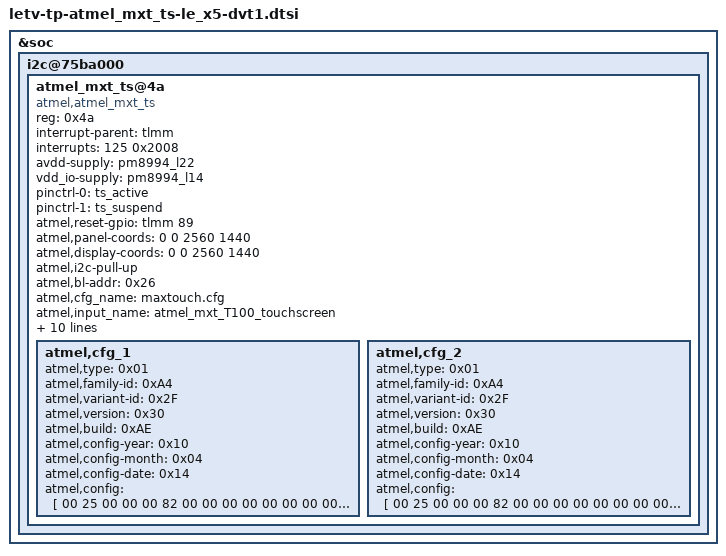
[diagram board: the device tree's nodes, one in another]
&soc {
	i2c@75ba000 {
		atmel_mxt_ts@4a {
			compatible = "atmel,atmel_mxt_ts";
			reg = <0x4a>;
			interrupt-parent = <&tlmm>;
			interrupts = <125 0x2008>;
			avdd-supply = <&pm8994_l22>;
			vdd_io-supply = <&pm8994_l14>;
			pinctrl-names = "pmx_ts_active", "pmx_ts_suspend";
			pinctrl-0 = <&ts_active>;
			pinctrl-1 = <&ts_suspend>;
			atmel,reset-gpio = <&tlmm 89 0>;
			atmel,panel-coords = <0 0 2560 1440>;
			atmel,display-coords = <0 0 2560 1440>;
			atmel,i2c-pull-up;
			atmel,bl-addr = <0x26>;
			atmel,cfg_name = "maxtouch.cfg";
			atmel,input_name = "atmel_mxt_T100_touchscreen";
			atmel,fw_version = "30AE";
			atmel,number-of-x-lines = <27>;
			atmel,number-of-y-lines = <16>;
			atmel,rawdata_threshold_max = <30500>;
			atmel,rawdata_threshold_min = <24500>;
			atmel,rawdata_shift_value = <4000>;
			atmel,rawdata_tkey_threshold_max = <26500>;
			atmel,rawdata_tkey_threshold_min = <21500>;
			atmel,rawdata_tkey_shift_value = <3500>;
			atmel,cap-button-codes = <158 172 0x244>;
			status = "ok";
			atmel,cfg_1 {
				atmel,type = <0x01>;
				atmel,family-id = <0xA4>;
				atmel,variant-id = <0x2F>;
				atmel,version = <0x30>;
				atmel,build = <0xAE>;
				atmel,config-year = <0x10>;
				atmel,config-month = <0x04>;
				atmel,config-date = <0x14>;
				atmel,config = [
					00 25 00 00 00 82 00 00
					00 00 00 00 00 00 00 00
					00 00 00 00 00 00 00 00
					00 00 00 00 00 00 00 00
					00 00 00 00 00 00 00 00
					00 00 00 00 00 00 00 00
					00 00 00 00 00 00 00 00
					00 00 00 00 00 00 00 00
					00 00 00 00 00 00 00 00
					00 00 00 00 00 00 00 00
					00 00 00 00 00 00 00 00
					00 00 00 00 00 00 00 00
					00 00 00 00 00 00 00 00
					00 00 00 00 00 00 00 00
					00 00 00 00 00 00 00 00
					00 00 00 00 00 00 00 00
					00 00 00 00 00 00 00 00
					00 44 00 00 00 49 00 00
					00 00 00 00 00 00 00 00
					00 00 00 00 00 00 00 00
					00 00 00 00 00 00 00 00
					00 00 00 00 00 00 00 00
					00 00 00 00 00 00 00 00
					00 00 00 00 00 00 00 00
					00 00 00 00 00 00 00 00
					00 00 00 00 00 00 00 00
					00 00 00 00 00 00 00
					00 26 00 00 00 40 01 1E
					AE 10 04 14 00 00 00 00
					00 00 00 00 00 00 00 00
					00 00 00 00 00 00 00 00
					00 00 00 00 00 00 00 00
					00 00 00 00 00 00 00 00
					00 00 00 00 00 00 00 00
					00 00 00 00 00 00 00 00
					00 00 00 00 00 00
					00 47 00 00 00 C8 00 64
					14 32 0A 22 3C 14 19 00
					32 14 14 00 00 1E C8 0F
					00 02 00 14 00 32 02 F0
					78 32 00 00 00 00 64 14
					32 0A 22 3C 14 19 00 00
					32 14 14 00 00 1E C8 0F
					00 02 00 14 00 32 02 F0
					78 32 00 00 84 00 50 0A
					19 04 22 28 0A 0F 00 00
					20 0F 14 00 50 0F 32 05
					00 01 00 00 00 0C 43 FA
					3C 1E 00 00 85 00 01 01
					02 02 00 00 00 1C 01 19
					01 19 00 00 00 00 00 00
					00 00 00 00 00 00 18 0C
					00 00 00 14 14 0A 00 00
					0F 0F 05 00 00 14 14 14
					00 00 01 0F 01 01 00 00
					00 00 00 00 00 00 00 00
					00 00 00 00 00 00 00 00
					00 00 00 00 00 00 00 00
					00 00 00 00 00 00 00 00
					00 00 00 00 00 00 00 00
					00 00 00 00 00 00 00 00
					00 00 00 00 00 00
					00 6E 00 00 00 28 89 03
					51 03 89 05 B9 04 E1 05
					91 06 89 09 E9 08 A1 0A
					81 0B 51 09 61 09 59 0B
					49 0A E1 09 01 07 01 00
					01 00 01 00 01 00
					00 6E 00 01 00 28 00 00
					00 00 00 00 00 00 00 00
					00 00 00 00 00 00 00 00
					00 00 00 00 00 00 00 00
					00 00 00 00 00 00 00 00
					00 00 00 00 00 00
					00 6E 00 02 00 28 00 00
					00 00 00 00 00 00 00 00
					00 00 00 00 00 00 00 00
					00 00 00 00 00 00 00 00
					00 00 00 00 00 00 00 00
					00 00 00 00 00 00
					00 6E 00 03 00 28 D1 03
					39 04 39 05 79 05 F1 05
					41 07 E9 09 21 09 11 0B
					21 0B 41 09 59 09 49 0B
					51 0B 51 0A 31 08 01 00
					01 00 01 00 01 00
					00 6E 00 04 00 28 00 00
					00 00 00 00 00 00 00 00
					00 00 00 00 00 00 00 00
					00 00 00 00 00 00 00 00
					00 00 00 00 00 00 00 00
					00 00 00 00 00 00
					00 6E 00 05 00 28 00 00
					00 00 00 00 00 00 00 00
					00 00 00 00 00 00 00 00
					00 00 00 00 00 00 00 00
					00 00 00 00 00 00 00 00
					00 00 00 00 00 00
					00 6E 00 06 00 28 6B 04
					6B 04 53 04 63 04 53 04
					43 04 2B 04 2B 04 0B 04
					03 04 1B 04 23 04 0B 04
					13 04 1B 04 3B 04 03 00
					03 00 03 00 03 00
					00 6E 00 07 00 28 00 00
					00 00 00 00 00 00 00 00
					00 00 00 00 00 00 00 00
					00 00 00 00 00 00 00 00
					00 00 00 00 00 00 00 00
					00 00 00 00 00 00
					00 6E 00 08 00 28 00 00
					00 00 00 00 00 00 00 00
					00 00 00 00 00 00 00 00
					00 00 00 00 00 00 00 00
					00 00 00 00 00 00 00 00
					00 00 00 00 00 00
					00 07 00 00 00 05 08 08
					1E C2 00
					00 08 00 00 00 0F 50 00
					05 05 00 05 00 00 00 00
					0B 08 01 01 80
					00 0F 00 00 00 0B 8B 1C
					10 01 03 00 07 32 02 05
					00
					00 12 00 00 00 02 00 00
					00 13 00 00 00 06 00 00
					00 00 00 00
					00 19 00 00 00 10 03 00
					30 75 D8 59 00 00 00 00
					FE A0 0F 00 00 00
					00 28 00 00 00 07 31 00
					00 3C 3C 00 01
					00 2A 00 00 00 0E 01 00
					FF 2D FF 05 00 00 00 00
					C8 03 00 00
					00 2B 00 00 00 11 00 00
					00 00 00 00 00 00 00 00
					00 00 00 00 00 00 00
					00 2E 00 00 00 0C 00 00
					08 06 01 00 00 32 00 01
					00 00
					00 2F 00 00 00 2F 00 00
					00 00 00 00 00 00 00 00
					00 00 00 00 00 00 00 00
					00 00 00 00 00 00 00 00
					00 00 00 00 00 00 00 00
					00 00 00 00 00 00 00 00
					00 00 00 00 00
					00 38 00 00 00 24 03 00
					01 2F 04 04 04 04 04 04
					04 04 04 04 04 04 04 04
					04 04 04 04 04 04 04 04
					04 04 07 07 08 07 00 00
					00 00
					00 3D 00 00 00 05 03 00
					00 E8 03
					00 3D 00 01 00 05 00 00
					00 00 00
					00 3D 00 02 00 05 00 00
					00 00 00
					00 3D 00 03 00 05 00 00
					00 00 00
					00 3D 00 04 00 05 00 00
					00 00 00
					00 3D 00 05 00 05 00 00
					00 00 00
					00 41 00 00 00 17 81 0A
					00 00 00 00 00 00 00 00
					0A 00 00 00 00 00 00 12
					00 00 00 00 00
					00 41 00 01 00 17 00 00
					00 00 00 00 00 00 00 00
					00 00 00 00 00 00 00 00
					00 00 00 00 00
					00 41 00 02 00 17 00 00
					00 00 00 00 00 00 00 00
					00 00 00 00 00 00 00 00
					00 00 00 00 00
					00 46 00 00 00 0A 03 C8
					00 26 00 00 3F 00 00 00
					00 46 00 01 00 0A 03 78
					00 68 00 00 02 01 00 07
					00 46 00 02 00 0A 03 78
					00 64 00 00 1E 0A 00 11
					00 46 00 03 00 0A 00 78
					00 50 00 00 01 1F 00 00
					00 46 00 04 00 0A 03 72
					00 68 00 00 02 20 00 07
					00 46 00 05 00 0A 03 72
					00 64 00 00 1E 2A 00 11
					00 46 00 06 00 0A 00 72
					00 4E 00 00 00 3E 00 00
					00 46 00 07 00 0A 00 72
					00 50 00 00 01 3F 00 00
					00 46 00 08 00 0A 03 0D
					00 68 00 00 02 40 00 07
					00 46 00 09 00 0A 03 0D
					00 64 00 00 1E 4A 00 11
					00 46 00 0A 00 0A 00 0D
					00 4E 00 00 00 5E 00 00
					00 46 00 0B 00 0A 00 0D
					00 50 00 00 01 5F 00 00
					00 46 00 0C 00 0A 03 79
					00 3D 00 00 01 60 00 00
					00 46 00 0D 00 0A 03 73
					00 3D 00 00 01 61 00 00
					00 46 00 0E 00 0A 03 78
					00 3D 00 00 01 62 00 00
					00 46 00 0F 00 0A 03 72
					00 3D 00 00 01 63 00 00
					00 46 00 10 00 0A 00 00
					00 00 00 00 00 00 00 00
					00 46 00 11 00 0A 00 00
					00 00 00 00 00 00 00 00
					00 46 00 12 00 0A 03 16
					00 2E 00 00 04 6A 00 00
					00 46 00 13 00 0A 03 16
					00 48 00 00 13 6B 00 00
					00 46 00 14 00 0A 03 18
					00 2E 00 00 04 68 00 00
					00 46 00 15 00 0A 03 18
					00 48 00 00 13 69 00 00
					00 46 00 16 00 0A 03 18
					00 64 00 00 2B 79 00 00
					00 46 00 17 00 0A 03 1A
					00 48 00 00 13 67 00 00
					00 46 00 18 00 0A 00 00
					00 00 00 00 00 00 00 00
					00 46 00 19 00 0A 03 1A
					00 2E 00 00 04 66 00 00
					00 46 00 1A 00 0A 03 1A
					00 64 00 00 2B 78 00 00
					00 46 00 1B 00 0A 03 18
					00 64 00 00 20 7D 00 00
					00 46 00 1C 00 0A 03 1A
					00 64 00 00 20 7E 00 00
					00 46 00 1D 00 0A 03 16
					00 64 00 00 20 7F 00 00
					00 46 00 1E 00 0A 00 18
					00 41 00 00 01 82 00 00
					00 46 00 1F 00 0A 00 1A
					00 41 00 00 01 83 00 00
					00 46 00 20 00 0A 00 16
					00 41 00 00 01 84 00 00
					00 46 00 21 00 0A 01 18
					00 47 00 00 4C 87 00 00
					00 46 00 22 00 0A 01 1A
					00 47 00 00 4C 88 00 00
					00 46 00 23 00 0A 01 16
					00 47 00 00 4C 89 00 00
					00 46 00 24 00 0A 01 13
					00 06 00 00 02 8C 00 00
					00 46 00 25 00 0A 01 13
					00 64 00 00 1F 8D 00 00
					00 46 00 26 00 0A 01 12
					00 64 00 00 1F 8E 00 00
					00 46 00 27 00 0A 00 0B
					00 06 00 00 02 8F 00 00
					00 48 00 00 00 59 7D 00
					00 01 00 04 0A 0A 00 08
					2D 00 00 04 31 37 65 0E
					00 19 09 00 00 00 00 00
					0A 00 00 00 00 0C 00 00
					00 00 00 00 0D 00 09 00
					00 00 00 00 0C 00 00 00
					00 0C 00 00 00 00 00 02
					1E 85 09 69 94 C6 6E 00
					20 20 20 20 00 28 28 28
					28 00 00 03 00 85 00 00
					00 00 00 00 00 00 00
					00 4D 00 00 00 02 00 00
					00 4E 00 00 00 0C 84 05
					03 0A 19 01 18 00 8C 00
					00 00
					00 4F 00 00 00 04 00 00
					00 00
					00 4F 00 01 00 04 00 00
					00 00
					00 4F 00 02 00 04 00 00
					00 00
					00 50 00 00 00 0E 03 00
					6E 14 0A C5 00 46 1E 01
					00 00 00 03
					00 51 00 00 00 12 00 00
					00 00 00 00 00 00 00 00
					00 00 00 00 00 00 00 00
					00 51 00 01 00 12 00 00
					00 00 00 00 00 00 00 00
					00 00 00 00 00 00 00 00
					00 54 00 00 00 04 00 00
					00 00
					00 5D 00 00 00 1E 0F 9F
					05 00 00 00 00 F6 09 FF
					0F FF 0F 00 64 00 14 04
					00 00 2C 01 2C 01 00 14
					00 14 00 00
					00 63 00 00 00 0C 00 00
					00 00 00 00 00 00 00 00
					00 00
					00 64 00 00 00 45 83 35
					01 01 00 00 0A 88 00 1C
					2D 09 0A FF 09 17 20 23
					31 00 10 2D 04 04 9F 05
					1F 2F 0C 09 28 0F 19 00
					50 0F 32 05 00 01 00 00
					00 0C 43 FA 3C 1E 00 1E
					00 64 14 05 00 00 A3 31
					A6 2D 00 25 00 00 32 96
					00 19 87
					00 65 00 00 00 20 00 00
					00 00 00 00 00 00 00 00
					00 00 00 00 00 00 00 00
					00 00 00 00 00 00 00 00
					00 00 00 00 00 00
					00 68 00 00 00 0B 01 00
					50 0A 19 04 22 28 0A 0F
					06
					00 6C 00 00 00 4B 9D 00
					00 01 01 00 00 04 00 00
					00 00 00 00 00 00 00 00
					00 20 00 00 00 00 20 00
					00 00 00 00 00 06 00 01
					00 00 00 00 00 30 00 00
					00 00 30 00 00 00 00 00
					03 0C 64 01 00 00 00 00
					00 40 00 00 00 00 40 00
					00 00 00 00 14 00 85 00
					00
					00 6D 00 00 00 09 42 00
					05 00 00 00 00 00 03
					00 6F 00 00 00 1E 00 00
					55 50 18 18 05 05 00 FF
					00 00 00 00 00 00 00 00
					05 00 35 DC 00 23 00 01
					0A 00 32 3C
					00 6F 00 01 00 1E 00 00
					00 00 00 00 00 00 00 00
					00 00 00 00 00 00 00 00
					00 00 00 00 00 00 00 01
					00 00 00 00
					00 6F 00 02 00 1E 00 00
					55 50 40 40 00 00 00 00
					00 00 00 00 00 00 00 00
					00 00 00 00 00 2D 00 01
					00 00 00 00
					00 70 00 00 00 05 00 00
					00 00 00
					00 70 00 01 00 05 00 00
					00 00 00
					00 71 00 00 00 03 05 00
					08
					00 73 00 00 00 14 06 00
					00 FF FF 00 00 FF FF 28
					00 3C 00 02 3E 02 00 86
					00 23
					00 74 00 00 00 FF 00 00
					00 00 00 00 00 00 00 00
					00 00 00 00 00 00 00 00
					00 00 00 00 00 00 00 00
					00 00 00 00 00 00 00 00
					00 00 00 00 00 00 00 00
					00 00 00 00 00 00 00 00
					00 00 00 00 00 00 00 00
					00 00 00 00 00 00 00 00
					00 00 00 00 00 00 00 00
					00 00 00 00 00 00 00 00
					00 00 00 00 00 00 00 00
					00 00 00 00 00 00 00 00
					00 00 00 00 00 00 00 00
					00 00 00 00 00 00 00 00
					00 00 00 00 00 00 00 00
					00 00 00 00 00 00 00 00
					00 00 00 00 00 00 00 00
					00 00 00 00 00 00 00 00
					00 00 00 00 00 00 00 00
					00 00 00 00 00 00 00 00
					00 00 00 00 00 00 00 00
					00 00 00 00 00 00 00 00
					00 00 00 00 00 00 00 00
					00 00 00 00 00 00 00 00
					00 00 00 00 00 00 00 00
					00 00 00 00 00 00 00 00
					00 00 00 00 00 00 00 00
					00 00 00 00 00 00 00 00
					00 00 00 00 00 00 00 00
					00 00 00 00 00 00 00 00
					00 00 00 00 00 00 00 00
					00 00 00 00 00
					00 79 00 00 00 03 00 00
					00
					00 7C 00 00 00 07 0B 01
					07 08 80 3E 82
					00 7D 00 00 00 01 03
				];
			};
			atmel,cfg_2 {
				atmel,type = <0x01>;
				atmel,family-id = <0xA4>;
				atmel,variant-id = <0x2F>;
				atmel,version = <0x30>;
				atmel,build = <0xAE>;
				atmel,config-year = <0x10>;
				atmel,config-month = <0x04>;
				atmel,config-date = <0x14>;
				atmel,config = [
					00 25 00 00 00 82 00 00
					00 00 00 00 00 00 00 00
					00 00 00 00 00 00 00 00
					00 00 00 00 00 00 00 00
					00 00 00 00 00 00 00 00
					00 00 00 00 00 00 00 00
					00 00 00 00 00 00 00 00
					00 00 00 00 00 00 00 00
					00 00 00 00 00 00 00 00
					00 00 00 00 00 00 00 00
					00 00 00 00 00 00 00 00
					00 00 00 00 00 00 00 00
					00 00 00 00 00 00 00 00
					00 00 00 00 00 00 00 00
					00 00 00 00 00 00 00 00
					00 00 00 00 00 00 00 00
					00 00 00 00 00 00 00 00
					00 44 00 00 00 49 00 00
					00 00 00 00 00 00 00 00
					00 00 00 00 00 00 00 00
					00 00 00 00 00 00 00 00
					00 00 00 00 00 00 00 00
					00 00 00 00 00 00 00 00
					00 00 00 00 00 00 00 00
					00 00 00 00 00 00 00 00
					00 00 00 00 00 00 00 00
					00 00 00 00 00 00 00
					00 26 00 00 00 40 01 1E
					AE 10 04 14 00 00 00 00
					00 00 00 00 00 00 00 00
					00 00 00 00 00 00 00 00
					00 00 00 00 00 00 00 00
					00 00 00 00 00 00 00 00
					00 00 00 00 00 00 00 00
					00 00 00 00 00 00 00 00
					00 00 00 00 00 00
					00 47 00 00 00 C8 00 64
					14 32 0A 22 3C 14 19 00
					32 14 14 00 00 1E C8 0F
					00 02 00 14 00 32 02 F0
					78 32 00 00 00 00 64 14
					32 0A 22 3C 14 19 00 00
					32 14 14 00 00 1E C8 0F
					00 02 00 14 00 32 02 F0
					78 32 00 00 84 00 50 0A
					19 04 22 28 0A 0F 00 00
					20 0F 14 00 50 0F 32 05
					00 01 00 00 00 0C 43 FA
					3C 1E 00 00 85 00 01 01
					02 02 00 00 00 1C 01 19
					01 19 00 00 00 00 00 00
					00 00 00 00 00 00 18 0C
					00 00 00 14 14 0A 00 00
					0F 0F 05 00 00 14 14 14
					00 00 01 0F 01 01 00 00
					00 00 00 00 00 00 00 00
					00 00 00 00 00 00 00 00
					00 00 00 00 00 00 00 00
					00 00 00 00 00 00 00 00
					00 00 00 00 00 00 00 00
					00 00 00 00 00 00 00 00
					00 00 00 00 00 00
					00 6E 00 00 00 28 89 03
					51 03 89 05 B9 04 E1 05
					91 06 89 09 E9 08 A1 0A
					81 0B 51 09 61 09 59 0B
					49 0A E1 09 01 07 01 00
					01 00 01 00 01 00
					00 6E 00 01 00 28 00 00
					00 00 00 00 00 00 00 00
					00 00 00 00 00 00 00 00
					00 00 00 00 00 00 00 00
					00 00 00 00 00 00 00 00
					00 00 00 00 00 00
					00 6E 00 02 00 28 00 00
					00 00 00 00 00 00 00 00
					00 00 00 00 00 00 00 00
					00 00 00 00 00 00 00 00
					00 00 00 00 00 00 00 00
					00 00 00 00 00 00
					00 6E 00 03 00 28 D1 03
					39 04 39 05 79 05 F1 05
					41 07 E9 09 21 09 11 0B
					21 0B 41 09 59 09 49 0B
					51 0B 51 0A 31 08 01 00
					01 00 01 00 01 00
					00 6E 00 04 00 28 00 00
					00 00 00 00 00 00 00 00
					00 00 00 00 00 00 00 00
					00 00 00 00 00 00 00 00
					00 00 00 00 00 00 00 00
					00 00 00 00 00 00
					00 6E 00 05 00 28 00 00
					00 00 00 00 00 00 00 00
					00 00 00 00 00 00 00 00
					00 00 00 00 00 00 00 00
					00 00 00 00 00 00 00 00
					00 00 00 00 00 00
					00 6E 00 06 00 28 6B 04
					6B 04 53 04 63 04 53 04
					43 04 2B 04 2B 04 0B 04
					03 04 1B 04 23 04 0B 04
					13 04 1B 04 3B 04 03 00
					03 00 03 00 03 00
					00 6E 00 07 00 28 00 00
					00 00 00 00 00 00 00 00
					00 00 00 00 00 00 00 00
					00 00 00 00 00 00 00 00
					00 00 00 00 00 00 00 00
					00 00 00 00 00 00
					00 6E 00 08 00 28 00 00
					00 00 00 00 00 00 00 00
					00 00 00 00 00 00 00 00
					00 00 00 00 00 00 00 00
					00 00 00 00 00 00 00 00
					00 00 00 00 00 00
					00 07 00 00 00 05 08 08
					1E C2 00
					00 08 00 00 00 0F 50 00
					05 05 00 05 00 00 00 00
					0B 08 01 01 80
					00 0F 00 00 00 0B 8B 1C
					10 01 03 00 07 32 02 05
					00
					00 12 00 00 00 02 00 00
					00 13 00 00 00 06 00 00
					00 00 00 00
					00 19 00 00 00 10 03 00
					30 75 D8 59 00 00 00 00
					FE A0 0F 00 00 00
					00 28 00 00 00 07 31 00
					00 3C 3C 00 01
					00 2A 00 00 00 0E 01 00
					FF 2D FF 05 00 00 00 00
					C8 03 00 00
					00 2B 00 00 00 11 00 00
					00 00 00 00 00 00 00 00
					00 00 00 00 00 00 00
					00 2E 00 00 00 0C 00 00
					08 06 01 00 00 32 00 01
					00 00
					00 2F 00 00 00 2F 00 00
					00 00 00 00 00 00 00 00
					00 00 00 00 00 00 00 00
					00 00 00 00 00 00 00 00
					00 00 00 00 00 00 00 00
					00 00 00 00 00 00 00 00
					00 00 00 00 00
					00 38 00 00 00 24 03 00
					01 2F 04 04 04 04 04 04
					04 04 04 04 04 04 04 04
					04 04 04 04 04 04 04 04
					04 04 07 07 08 07 00 00
					00 00
					00 3D 00 00 00 05 03 00
					00 E8 03
					00 3D 00 01 00 05 00 00
					00 00 00
					00 3D 00 02 00 05 00 00
					00 00 00
					00 3D 00 03 00 05 00 00
					00 00 00
					00 3D 00 04 00 05 00 00
					00 00 00
					00 3D 00 05 00 05 00 00
					00 00 00
					00 41 00 00 00 17 81 0A
					00 00 00 00 00 00 00 00
					0A 00 00 00 00 00 00 12
					00 00 00 00 00
					00 41 00 01 00 17 00 00
					00 00 00 00 00 00 00 00
					00 00 00 00 00 00 00 00
					00 00 00 00 00
					00 41 00 02 00 17 00 00
					00 00 00 00 00 00 00 00
					00 00 00 00 00 00 00 00
					00 00 00 00 00
					00 46 00 00 00 0A 03 C8
					00 26 00 00 3F 00 00 00
					00 46 00 01 00 0A 03 78
					00 68 00 00 02 01 00 07
					00 46 00 02 00 0A 03 78
					00 64 00 00 1E 0A 00 11
					00 46 00 03 00 0A 00 78
					00 50 00 00 01 1F 00 00
					00 46 00 04 00 0A 03 72
					00 68 00 00 02 20 00 07
					00 46 00 05 00 0A 03 72
					00 64 00 00 1E 2A 00 11
					00 46 00 06 00 0A 00 72
					00 4E 00 00 00 3E 00 00
					00 46 00 07 00 0A 00 72
					00 50 00 00 01 3F 00 00
					00 46 00 08 00 0A 03 0D
					00 68 00 00 02 40 00 07
					00 46 00 09 00 0A 03 0D
					00 64 00 00 1E 4A 00 11
					00 46 00 0A 00 0A 00 0D
					00 4E 00 00 00 5E 00 00
					00 46 00 0B 00 0A 00 0D
					00 50 00 00 01 5F 00 00
					00 46 00 0C 00 0A 03 79
					00 3D 00 00 01 60 00 00
					00 46 00 0D 00 0A 03 73
					00 3D 00 00 01 61 00 00
					00 46 00 0E 00 0A 03 78
					00 3D 00 00 01 62 00 00
					00 46 00 0F 00 0A 03 72
					00 3D 00 00 01 63 00 00
					00 46 00 10 00 0A 00 00
					00 00 00 00 00 00 00 00
					00 46 00 11 00 0A 00 00
					00 00 00 00 00 00 00 00
					00 46 00 12 00 0A 03 16
					00 2E 00 00 04 6A 00 00
					00 46 00 13 00 0A 03 16
					00 48 00 00 13 6B 00 00
					00 46 00 14 00 0A 03 18
					00 2E 00 00 04 68 00 00
					00 46 00 15 00 0A 03 18
					00 48 00 00 13 69 00 00
					00 46 00 16 00 0A 03 18
					00 64 00 00 2B 79 00 00
					00 46 00 17 00 0A 03 1A
					00 48 00 00 13 67 00 00
					00 46 00 18 00 0A 00 00
					00 00 00 00 00 00 00 00
					00 46 00 19 00 0A 03 1A
					00 2E 00 00 04 66 00 00
					00 46 00 1A 00 0A 03 1A
					00 64 00 00 2B 78 00 00
					00 46 00 1B 00 0A 03 18
					00 64 00 00 20 7D 00 00
					00 46 00 1C 00 0A 03 1A
					00 64 00 00 20 7E 00 00
					00 46 00 1D 00 0A 03 16
					00 64 00 00 20 7F 00 00
					00 46 00 1E 00 0A 00 18
					00 41 00 00 01 82 00 00
					00 46 00 1F 00 0A 00 1A
					00 41 00 00 01 83 00 00
					00 46 00 20 00 0A 00 16
					00 41 00 00 01 84 00 00
					00 46 00 21 00 0A 01 18
					00 47 00 00 4C 87 00 00
					00 46 00 22 00 0A 01 1A
					00 47 00 00 4C 88 00 00
					00 46 00 23 00 0A 01 16
					00 47 00 00 4C 89 00 00
					00 46 00 24 00 0A 01 13
					00 06 00 00 02 8C 00 00
					00 46 00 25 00 0A 01 13
					00 64 00 00 1F 8D 00 00
					00 46 00 26 00 0A 01 12
					00 64 00 00 1F 8E 00 00
					00 46 00 27 00 0A 00 0B
					00 06 00 00 02 8F 00 00
					00 48 00 00 00 59 7D 00
					00 01 00 04 0A 0A 00 08
					2D 00 00 04 31 37 65 0E
					00 19 09 00 00 00 00 00
					0A 00 00 00 00 0C 00 00
					00 00 00 00 0D 00 09 00
					00 00 00 00 0C 00 00 00
					00 0C 00 00 00 00 00 02
					1E 85 09 69 94 C6 6E 00
					20 20 20 20 00 28 28 28
					28 00 00 03 00 85 00 00
					00 00 00 00 00 00 00
					00 4D 00 00 00 02 00 00
					00 4E 00 00 00 0C 84 05
					03 0A 19 01 18 00 8C 00
					00 00
					00 4F 00 00 00 04 00 00
					00 00
					00 4F 00 01 00 04 00 00
					00 00
					00 4F 00 02 00 04 00 00
					00 00
					00 50 00 00 00 0E 03 00
					6E 14 0A C5 00 46 1E 01
					00 00 00 03
					00 51 00 00 00 12 00 00
					00 00 00 00 00 00 00 00
					00 00 00 00 00 00 00 00
					00 51 00 01 00 12 00 00
					00 00 00 00 00 00 00 00
					00 00 00 00 00 00 00 00
					00 54 00 00 00 04 00 00
					00 00
					00 5D 00 00 00 1E 0F 9F
					05 00 00 00 00 F6 09 FF
					0F FF 0F 00 64 00 14 04
					00 00 2C 01 2C 01 00 14
					00 14 00 00
					00 63 00 00 00 0C 00 00
					00 00 00 00 00 00 00 00
					00 00
					00 64 00 00 00 45 83 35
					01 01 00 00 0A 88 00 1C
					2D 09 0A FF 09 17 20 23
					31 00 10 2D 04 04 9F 05
					1F 2F 0C 09 28 0F 19 00
					50 0F 32 05 00 01 00 00
					00 0C 43 FA 3C 1E 00 1E
					00 64 14 05 00 00 A3 31
					A6 2D 00 25 00 00 32 96
					00 19 87
					00 65 00 00 00 20 00 00
					00 00 00 00 00 00 00 00
					00 00 00 00 00 00 00 00
					00 00 00 00 00 00 00 00
					00 00 00 00 00 00
					00 68 00 00 00 0B 01 00
					50 0A 19 04 22 28 0A 0F
					06
					00 6C 00 00 00 4B 9D 00
					00 01 01 00 00 04 00 00
					00 00 00 00 00 00 00 00
					00 20 00 00 00 00 20 00
					00 00 00 00 00 06 00 01
					00 00 00 00 00 30 00 00
					00 00 30 00 00 00 00 00
					03 0C 64 01 00 00 00 00
					00 40 00 00 00 00 40 00
					00 00 00 00 14 00 85 00
					00
					00 6D 00 00 00 09 42 00
					05 00 00 00 00 00 03
					00 6F 00 00 00 1E 00 00
					55 50 18 18 05 05 00 FF
					00 00 00 00 00 00 00 00
					05 00 35 DC 00 23 00 01
					0A 00 32 3C
					00 6F 00 01 00 1E 00 00
					00 00 00 00 00 00 00 00
					00 00 00 00 00 00 00 00
					00 00 00 00 00 00 00 01
					00 00 00 00
					00 6F 00 02 00 1E 00 00
					55 50 40 40 00 00 00 00
					00 00 00 00 00 00 00 00
					00 00 00 00 00 2D 00 01
					00 00 00 00
					00 70 00 00 00 05 00 00
					00 00 00
					00 70 00 01 00 05 00 00
					00 00 00
					00 71 00 00 00 03 05 00
					08
					00 73 00 00 00 14 06 00
					00 FF FF 00 00 FF FF 28
					00 3C 00 02 3E 02 00 86
					00 23
					00 74 00 00 00 FF 00 00
					00 00 00 00 00 00 00 00
					00 00 00 00 00 00 00 00
					00 00 00 00 00 00 00 00
					00 00 00 00 00 00 00 00
					00 00 00 00 00 00 00 00
					00 00 00 00 00 00 00 00
					00 00 00 00 00 00 00 00
					00 00 00 00 00 00 00 00
					00 00 00 00 00 00 00 00
					00 00 00 00 00 00 00 00
					00 00 00 00 00 00 00 00
					00 00 00 00 00 00 00 00
					00 00 00 00 00 00 00 00
					00 00 00 00 00 00 00 00
					00 00 00 00 00 00 00 00
					00 00 00 00 00 00 00 00
					00 00 00 00 00 00 00 00
					00 00 00 00 00 00 00 00
					00 00 00 00 00 00 00 00
					00 00 00 00 00 00 00 00
					00 00 00 00 00 00 00 00
					00 00 00 00 00 00 00 00
					00 00 00 00 00 00 00 00
					00 00 00 00 00 00 00 00
					00 00 00 00 00 00 00 00
					00 00 00 00 00 00 00 00
					00 00 00 00 00 00 00 00
					00 00 00 00 00 00 00 00
					00 00 00 00 00 00 00 00
					00 00 00 00 00 00 00 00
					00 00 00 00 00 00 00 00
					00 00 00 00 00
					00 79 00 00 00 03 00 00
					00
					00 7C 00 00 00 07 0B 01
					07 08 80 3E 82
					00 7D 00 00 00 01 03
				];
			};
		};
	};
};
